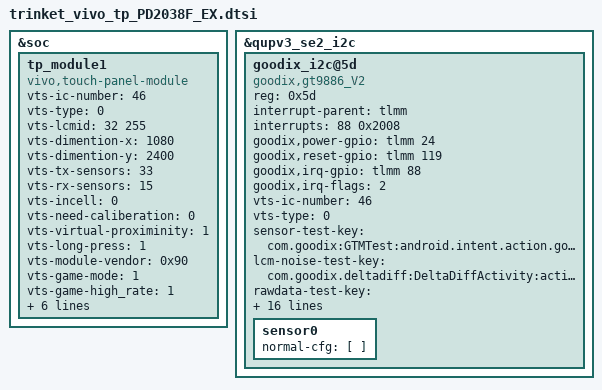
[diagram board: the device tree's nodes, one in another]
&soc {
	tp_module1 {
		compatible = "vivo,touch-panel-module";
		vts-ic-number=<46>;
		vts-type=<0>;
		vts-lcmid=<32 255>;
		vts-dimention-x=<1080>;
		vts-dimention-y=<2400>;
		vts-tx-sensors=<33>;
		vts-rx-sensors=<15>;
		vts-incell=<0>;
		vts-need-caliberation=<0>;
		vts-virtual-proximinity=<1>;
		vts-long-press=<1>;
		vts-module-vendor=<0x90>;
		vts-game-mode=<1>;
		vts-game-high_rate=<1>;//0:keep prev   1: high_rate  2:normal_rate 
		vts-game-idle-time=<10>;//0: keep prev  FF:ic default time , 0~ff: enter idle time    
		vts-fp-feedback=<1>;
		vts-input-method=<1>;
		vts-gesture=<1>;
		vts-screen-clock=<1>;
		vts-finger-mode=<1>;
		
	};

};

&qupv3_se2_i2c {
	status = "ok";

	goodix_i2c@5d {
		compatible = "goodix,gt9886_V2";
		reg = <0x5d>;
		interrupt-parent = <&tlmm>;
		interrupts = <88 0x2008>;

		goodix,power-gpio = <&tlmm 24 0x00>;	/*3V GPIO*/
		//avddvtouch-supply = <&pm8150_l17>;	/*3V PMIC*/

		//goodix,dvdd-gpio = <&tlmm 30 0x00>;	/*1.8V GPIO*/
		//vtouch-supply = <&pm6125_l9>;			/*1.8V PMIC*/

		/* pins used by touchscreen */
        //pinctrl-names = "pmx_ts_active","pmx_ts_suspend";
        //pinctrl-names ="default";
		//pinctrl-0 = <&ts_reset_active_s3706 &ts_int_active_s3706>;/* xxx is defined in  xxx-pinctrl.dtsi file*/
        //pinctrl-1 = <&ts_int_suspend_s3706 &ts_reset_suspend_s3706>;
		//pinctrl-0 = <&ts_reset_active_gt9886 &ts_int_active_gt9886>;

		goodix,reset-gpio = <&tlmm 119 0x00>;
        goodix,irq-gpio = <&tlmm 88 0x00>;
		goodix,irq-flags = <2>; /* 1:trigger rising, 2:trigger falling;*/

		vts-ic-number=<46>;
		vts-type=<0>;
		sensor-test-key= "com.goodix:GTMTest:android.intent.action.goodix:0:goodixTestResult";
		lcm-noise-test-key="com.goodix.deltadiff:DeltaDiffActivity:action.null:null:null";
		rawdata-test-key="com.goodix.deltadiff:DataShowActivity:null:null:null";
		rf-noise-test-key="com.goodix.deltadiff:BspTestActivity:com.goodix.deltadiff.action.Receiver:0:GOODIX_DELTA";

        goodix,panel-max-id = <10>;
        goodix,panel-max-x = <1080>;
        goodix,panel-max-y = <2340>;
        goodix,panel-max-w = <512>;
        goodix,panel-max-p = <512>;
		goodix,panel-key-map = <158 172 217>; /*KEY_BACK, KEY_HOMEPAGE, KEY_SEARCH*/
		goodix,power-on-delay-us = <300000>; /*300ms*/
		goodix,power-off-delay-us = <5000>;
		goodix,i2c-read-max-size = <2048>;/*i2c read max byte one time*/
		/*goodix,swap-axis;*/
		goodix,x2x;
		goodix,y2y;
		goodix,pen-enable;
		goodix,key-of-pen = <331 332>;/*BTN_STYLUS, BTN_STYLUS2*/
		sensor0 {
			normal-cfg = [
			];
		};
	};
};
